# STM32U5F7 register map
File version: 1.1
CPU: CM33 r0p1, little endian, MPU, FPU, 4 interrupt priority bits
Registers are 32-bit, read-write, reset 0x0 unless marked. A register's access mark holds for its fields unless they carry their own. Offsets are from the block's base; [hi:lo] are bit positions.

## DAC1 — Digital-to-analog converter
Base 0x46021800
Same registers: SEC_DAC1 0x56021800
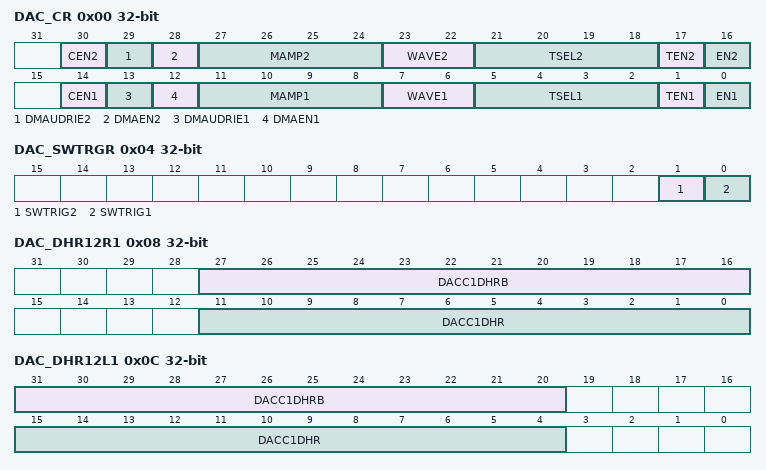
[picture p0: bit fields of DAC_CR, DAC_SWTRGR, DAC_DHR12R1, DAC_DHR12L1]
0x00 DAC_CR — DAC control register
  [30] CEN2 — DAC channel2 calibration enable
  [29] DMAUDRIE2 — DAC channel2 DMA underrun interrupt enable
  [28] DMAEN2 — DAC channel2 DMA enable
  [27:24] MAMP2 — DAC channel2 mask/amplitude selector
  [23:22] WAVE2 — DAC channel2 noise/triangle wave generation enable
  [21:18] TSEL2 — DAC channel2 trigger selection
  [17] TEN2 — DAC channel2 trigger enable
  [16] EN2 — DAC channel2 enable
  [14] CEN1 — DAC channel1 calibration enable
  [13] DMAUDRIE1 — DAC channel1 DMA Underrun Interrupt enable
  [12] DMAEN1 — DAC channel1 DMA enable
  [11:8] MAMP1 — DAC channel1 mask/amplitude selector
  [7:6] WAVE1 — DAC channel1 noise/triangle wave generation enable
  [5:2] TSEL1 — DAC channel1 trigger selection
  [1] TEN1 — DAC channel1 trigger enable
  [0] EN1 — DAC channel1 enable
0x04 DAC_SWTRGR wo — DAC software trigger register
  [1] SWTRIG2 — DAC channel2 software trigger
  [0] SWTRIG1 — DAC channel1 software trigger
0x08 DAC_DHR12R1 — DAC channel1 12-bit right-aligned data holding register
  [27:16] DACC1DHRB — DAC channel1 12-bit right-aligned data B
  [11:0] DACC1DHR — DAC channel1 12-bit right-aligned data
0x0C DAC_DHR12L1 — DAC channel1 12-bit left aligned data holding register
  [31:20] DACC1DHRB — DAC channel1 12-bit left-aligned data B
  [15:4] DACC1DHR — DAC channel1 12-bit left-aligned data
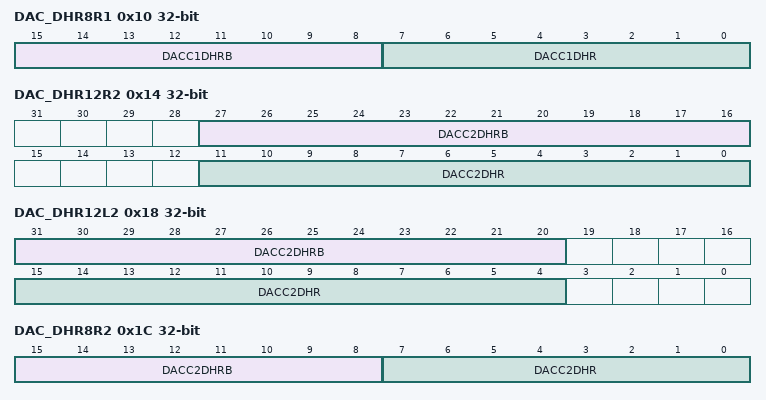
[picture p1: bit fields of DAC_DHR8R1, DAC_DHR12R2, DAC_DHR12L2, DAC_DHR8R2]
0x10 DAC_DHR8R1 — DAC channel1 8-bit right aligned data holding register
  [15:8] DACC1DHRB — DAC channel1 8-bit right-aligned Sdata
  [7:0] DACC1DHR — DAC channel1 8-bit right-aligned data
0x14 DAC_DHR12R2 — DAC channel2 12-bit right aligned data holding register
  [27:16] DACC2DHRB — DAC channel2 12-bit right-aligned data
  [11:0] DACC2DHR — DAC channel2 12-bit right-aligned data
0x18 DAC_DHR12L2 — DAC channel2 12-bit left aligned data holding register
  [31:20] DACC2DHRB — DAC channel2 12-bit left-aligned data B
  [15:4] DACC2DHR — DAC channel2 12-bit left-aligned data
0x1C DAC_DHR8R2 — DAC channel2 8-bit right-aligned data holding register
  [15:8] DACC2DHRB — DAC channel2 8-bit right-aligned data
  [7:0] DACC2DHR — DAC channel2 8-bit right-aligned data
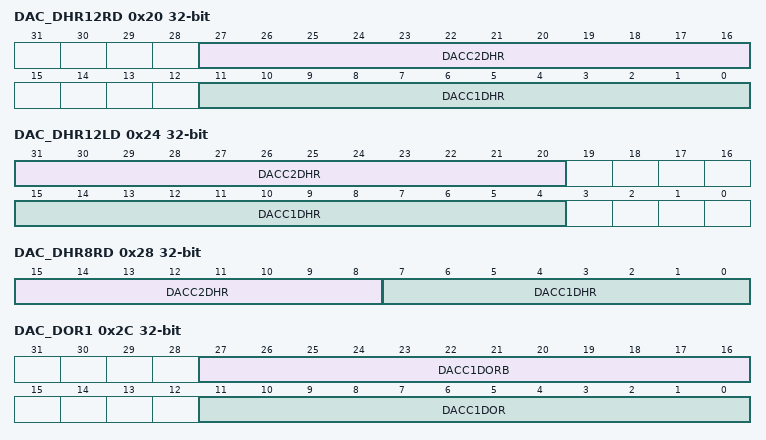
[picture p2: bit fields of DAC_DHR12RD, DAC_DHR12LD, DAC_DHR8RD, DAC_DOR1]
0x20 DAC_DHR12RD — Dual DAC 12-bit right-aligned data holding register
  [27:16] DACC2DHR — DAC channel2 12-bit right-aligned data
  [11:0] DACC1DHR — DAC channel1 12-bit right-aligned data
0x24 DAC_DHR12LD — DUAL DAC 12-bit left aligned data holding register
  [31:20] DACC2DHR — DAC channel2 12-bit left-aligned data
  [15:4] DACC1DHR — DAC channel1 12-bit left-aligned data
0x28 DAC_DHR8RD — DUAL DAC 8-bit right aligned data holding register
  [15:8] DACC2DHR — DAC channel2 8-bit right-aligned data
  [7:0] DACC1DHR — DAC channel1 8-bit right-aligned data
0x2C DAC_DOR1 ro — DAC channel1 data output register
  [27:16] DACC1DORB — DAC channel1 data output
  [11:0] DACC1DOR — DAC channel1 data output
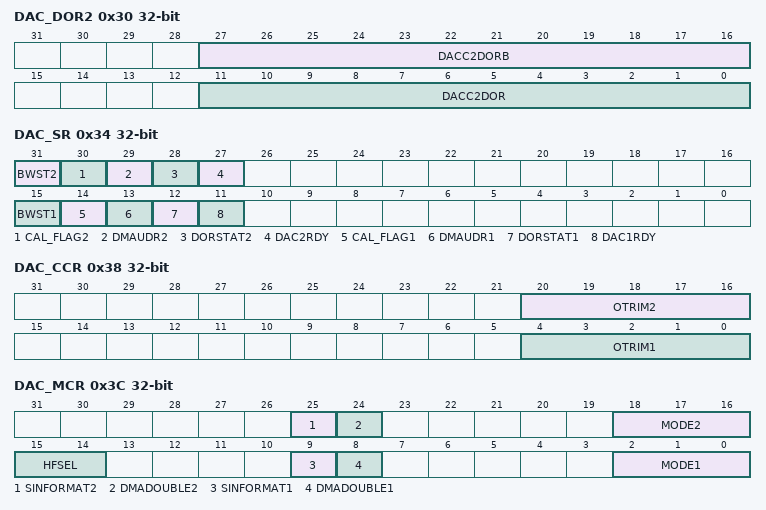
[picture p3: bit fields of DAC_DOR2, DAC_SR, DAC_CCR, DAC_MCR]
0x30 DAC_DOR2 ro — DAC channel2 data output register
  [27:16] DACC2DORB — DAC channel2 data output
  [11:0] DACC2DOR — DAC channel2 data output
0x34 DAC_SR access per field — DAC status register
  [31] BWST2 ro — DAC Channel 2 busy writing sample time flag
  [30] CAL_FLAG2 ro — DAC Channel 2 calibration offset status
  [29] DMAUDR2 rw — DAC channel2 DMA underrun flag
  [28] DORSTAT2 ro — DAC channel 2 output register status bit
  [27] DAC2RDY ro — DAC channel 2 ready status bit
  [15] BWST1 ro — DAC Channel 1 busy writing sample time flag
  [14] CAL_FLAG1 ro — DAC Channel 1 calibration offset status
  [13] DMAUDR1 rw — DAC channel1 DMA underrun flag
  [12] DORSTAT1 ro — DAC channel1 output register status bit
  [11] DAC1RDY ro — DAC channel1 ready status bit
0x38 DAC_CCR — DAC calibration control register
  [20:16] OTRIM2 — DAC Channel 2 offset trimming value
  [4:0] OTRIM1 — DAC Channel 1 offset trimming value
0x3C DAC_MCR — DAC mode control register
  [25] SINFORMAT2 — Enable signed format for DAC channel2
  [24] DMADOUBLE2 — DAC Channel2 DMA double data mode
  [18:16] MODE2 — DAC Channel 2 mode
  [15:14] HFSEL — High frequency interface mode selection
  [9] SINFORMAT1 — Enable signed format for DAC channel1
  [8] DMADOUBLE1 — DAC Channel1 DMA double data mode
  [2:0] MODE1 — DAC Channel 1 mode
0x40 DAC_SHSR1 — DAC Sample and Hold sample time register 1
  [9:0] TSAMPLE1 — DAC Channel 1 sample Time (only valid in sample & hold mode)
0x44 DAC_SHSR2 — DAC channel2 sample and hold sample time register
  [9:0] TSAMPLE2 — DAC Channel 2 sample Time (only valid in sample and hold mode)
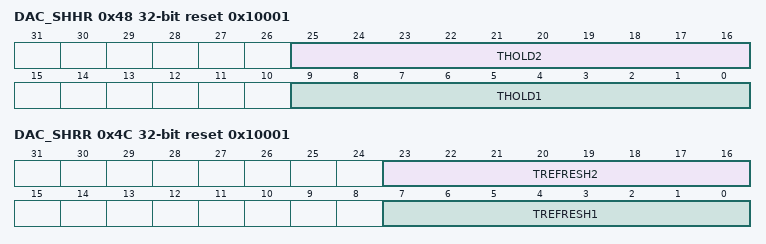
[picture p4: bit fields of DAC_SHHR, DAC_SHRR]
0x48 DAC_SHHR reset 0x10001 — DAC Sample and Hold hold time register
  [25:16] THOLD2 — DAC Channel 2 hold time (only valid in sample and hold mode)
  [9:0] THOLD1 — DAC Channel 1 hold Time (only valid in sample and hold mode)
0x4C DAC_SHRR reset 0x10001 — DAC Sample and Hold refresh time register
  [23:16] TREFRESH2 — DAC Channel 2 refresh Time (only valid in sample and hold mode)
  [7:0] TREFRESH1 — DAC Channel 1 refresh Time (only valid in sample and hold mode)
0x54 DAC_AUTOCR — Autonomous mode control register
  [22] AUTOMODE — DAC Autonomous mode

## Notices in the file
Copyright (c) 2024 STMicroelectronics.
SPDX-License-Identifier: Apache-2.0
Licensed under the Apache License, Version 2.0 (the "License");
you may not use this file except in compliance with the License.
You may obtain a copy of the License at
http://www.apache.org/licenses/LICENSE-2.0
Unless required by applicable law or agreed to in writing, software
distributed under the License is distributed on an "AS IS" BASIS,
WITHOUT WARRANTIES OR CONDITIONS OF ANY KIND, either express or implied.
See the License for the specific language governing permissions and
limitations under the License.
